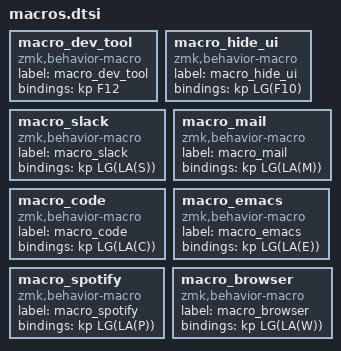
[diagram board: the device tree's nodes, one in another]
macro_dev_tool: macro_dev_tool{
compatible = "zmk,behavior-macro";
label = "macro_dev_tool";
#binding-cells = <0>;
bindings = <&kp F12>;
};
macro_hide_ui: macro_hide_ui{
compatible = "zmk,behavior-macro";
label = "macro_hide_ui";
#binding-cells = <0>;
bindings = <&kp LG(F10)>;
};
macro_slack: macro_slack{
compatible = "zmk,behavior-macro";
label = "macro_slack";
#binding-cells = <0>;
bindings = <&kp LG(LA(S))>;
};
macro_mail: macro_mail{
compatible = "zmk,behavior-macro";
label = "macro_mail";
#binding-cells = <0>;
bindings = <&kp LG(LA(M))>;
};
macro_code: macro_code{
compatible = "zmk,behavior-macro";
label = "macro_code";
#binding-cells = <0>;
bindings = <&kp LG(LA(C))>;
};
macro_emacs: macro_emacs{
compatible = "zmk,behavior-macro";
label = "macro_emacs";
#binding-cells = <0>;
bindings = <&kp LG(LA(E))>;
};
macro_spotify: macro_spotify{
compatible = "zmk,behavior-macro";
label = "macro_spotify";
#binding-cells = <0>;
bindings = <&kp LG(LA(P))>;
};
macro_browser: macro_browser{
compatible = "zmk,behavior-macro";
label = "macro_browser";
#binding-cells = <0>;
bindings = <&kp LG(LA(W))>;
};
